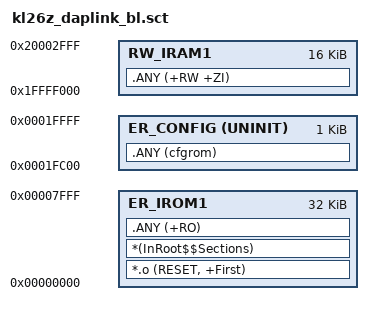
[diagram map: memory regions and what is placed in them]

LR_IROM1 0x00000000 0x8000  {    ; load region size_region (32k)
  ER_IROM1 0x00000000 0x8000  {  ; load address = execution address
   *.o (RESET, +First)
   *(InRoot$$Sections)
   .ANY (+RO)
  }
  RW_IRAM1 0x1FFFF000 0x4000 {   ; RAM (16k)
   .ANY (+RW +ZI)
  }
}
LR_CONFIG 0x0001FC00 0x400 {	 ; reserve last sector for config data
  ER_CONFIG 0x0001FC00 UNINIT 0x400 {
    .ANY (cfgrom)
  }
}
